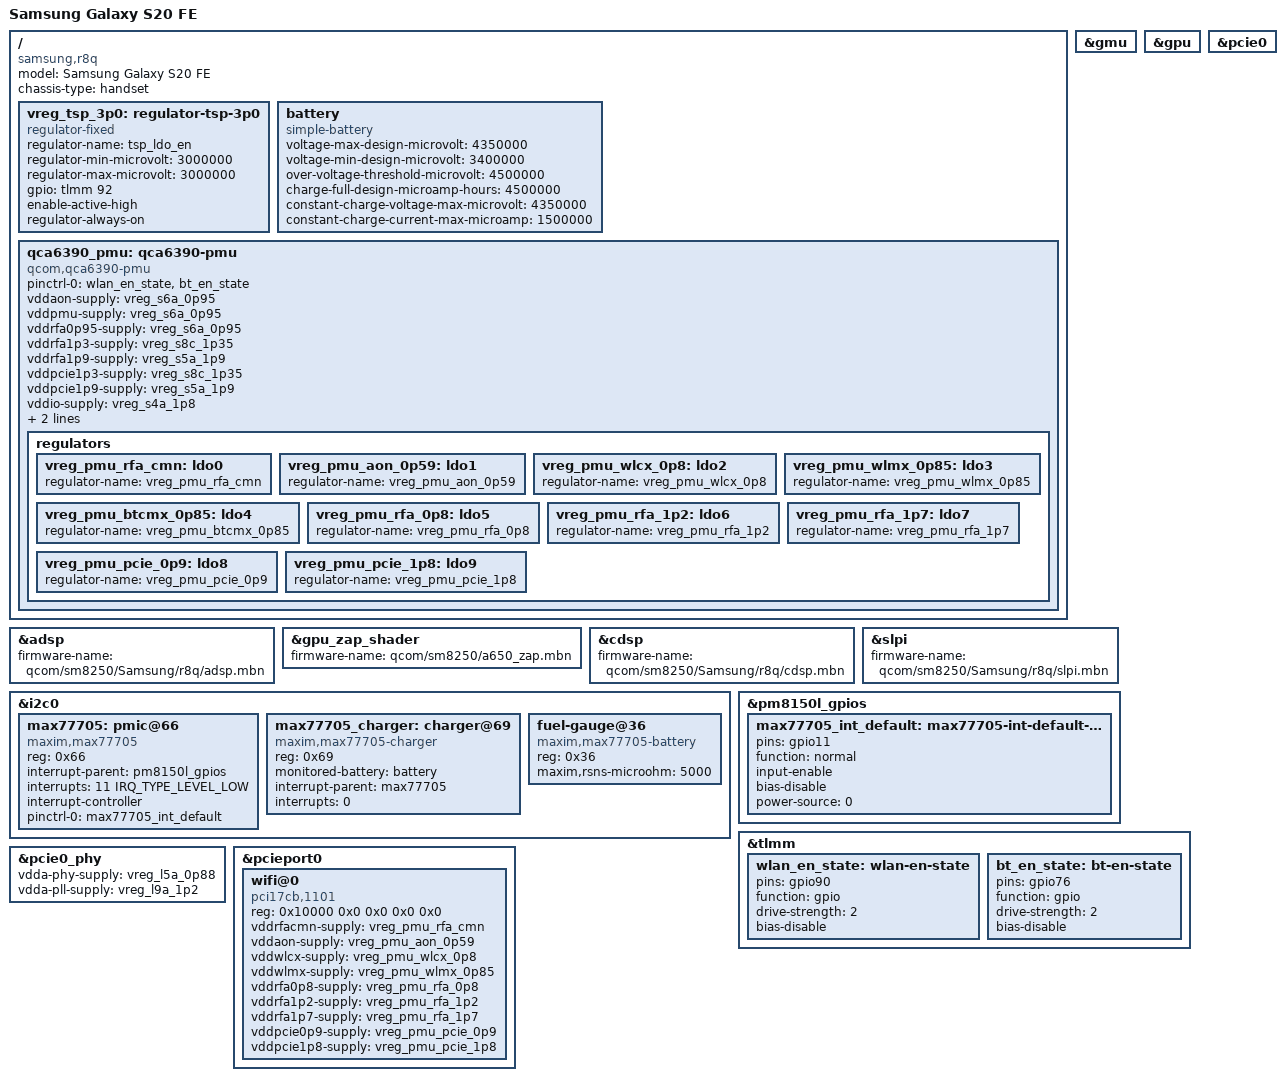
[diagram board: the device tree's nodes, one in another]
// SPDX-License-Identifier: GPL-2.0-only

/dts-v1/;

#include "sm8250-samsung-common.dtsi"

/ {
	model = "Samsung Galaxy S20 FE";
	compatible = "samsung,r8q", "qcom,sm8250";
	chassis-type = "handset";
	/* TSP power: discrete LDO on TLMM 92, always-on for bring-up. */
	vreg_tsp_3p0: regulator-tsp-3p0 {
		compatible = "regulator-fixed";
		regulator-name = "tsp_ldo_en";
		regulator-min-microvolt = <3000000>;
		regulator-max-microvolt = <3000000>;
		gpio = <&tlmm 92 GPIO_ACTIVE_HIGH>;
		enable-active-high;
		regulator-always-on;
	};

	/* EB-BG781ABY pack, 4500 mAh typical. */
	battery: battery {
		compatible = "simple-battery";
		voltage-max-design-microvolt = <4350000>;
		voltage-min-design-microvolt = <3400000>;
		over-voltage-threshold-microvolt = <4500000>;
		charge-full-design-microamp-hours = <4500000>;
		constant-charge-voltage-max-microvolt = <4350000>;
		constant-charge-current-max-microamp = <1500000>;
	};

		qca6390_pmu: qca6390-pmu {
			compatible = "qcom,qca6390-pmu";
	
			pinctrl-names = "default";
			pinctrl-0 = <&wlan_en_state>, <&bt_en_state>;
	
			vddaon-supply = <&vreg_s6a_0p95>;
			vddpmu-supply = <&vreg_s6a_0p95>;
			vddrfa0p95-supply = <&vreg_s6a_0p95>;
			vddrfa1p3-supply = <&vreg_s8c_1p35>;
			vddrfa1p9-supply = <&vreg_s5a_1p9>;
			vddpcie1p3-supply = <&vreg_s8c_1p35>;
			vddpcie1p9-supply = <&vreg_s5a_1p9>;
			vddio-supply = <&vreg_s4a_1p8>;
	
			wlan-enable-gpios = <&tlmm 90 GPIO_ACTIVE_HIGH>;
			bt-enable-gpios = <&tlmm 76 GPIO_ACTIVE_HIGH>;
	
			regulators {
				vreg_pmu_rfa_cmn: ldo0 {
					regulator-name = "vreg_pmu_rfa_cmn";
				};
				vreg_pmu_aon_0p59: ldo1 {
					regulator-name = "vreg_pmu_aon_0p59";
				};
				vreg_pmu_wlcx_0p8: ldo2 {
					regulator-name = "vreg_pmu_wlcx_0p8";
				};
				vreg_pmu_wlmx_0p85: ldo3 {
					regulator-name = "vreg_pmu_wlmx_0p85";
				};
				vreg_pmu_btcmx_0p85: ldo4 {
					regulator-name = "vreg_pmu_btcmx_0p85";
				};
				vreg_pmu_rfa_0p8: ldo5 {
					regulator-name = "vreg_pmu_rfa_0p8";
				};
				vreg_pmu_rfa_1p2: ldo6 {
					regulator-name = "vreg_pmu_rfa_1p2";
				};
				vreg_pmu_rfa_1p7: ldo7 {
					regulator-name = "vreg_pmu_rfa_1p7";
				};
				vreg_pmu_pcie_0p9: ldo8 {
					regulator-name = "vreg_pmu_pcie_0p9";
				};
				vreg_pmu_pcie_1p8: ldo9 {
					regulator-name = "vreg_pmu_pcie_1p8";
				};
			};
		};
};

&adsp {
	firmware-name = "qcom/sm8250/Samsung/r8q/adsp.mbn";
	status = "okay";
};

&gmu {
	status = "okay";
};

&gpu {
	status = "okay";
};

&gpu_zap_shader {
	/* Samsung-signed zap; generic one is rejected by Samsung TZ. */
	firmware-name = "qcom/sm8250/a650_zap.mbn";
};

&cdsp {
	firmware-name = "qcom/sm8250/Samsung/r8q/cdsp.mbn";
	status = "okay";
};

&slpi {
	firmware-name = "qcom/sm8250/Samsung/r8q/slpi.mbn";
	status = "okay";
};

&i2c0 {
	/* SE0 carries the Maxim MAX77705 companion PMIC + fuel gauge. */
	status = "okay";

	max77705: pmic@66 {
		compatible = "maxim,max77705";
		reg = <0x66>;
		interrupt-parent = <&pm8150l_gpios>;
		interrupts = <11 IRQ_TYPE_LEVEL_LOW>;
		interrupt-controller;
		#interrupt-cells = <1>;
		pinctrl-names = "default";
		pinctrl-0 = <&max77705_int_default>;
	};

	max77705_charger: charger@69 {
		compatible = "maxim,max77705-charger";
		reg = <0x69>;
		monitored-battery = <&battery>;
		interrupt-parent = <&max77705>;
		interrupts = <0>;
	};

	/* IRQ-less on purpose: telemetry survives MFD probe failure. */
	fuel-gauge@36 {
		compatible = "maxim,max77705-battery";
		reg = <0x36>;
		maxim,rsns-microohm = <5000>;
	};
};


&pm8150l_gpios {
	max77705_int_default: max77705-int-default-state {
		pins = "gpio11";
		function = "normal";
		input-enable;
		bias-disable;
		power-source = <0>;
	};
};

&tlmm {
	wlan_en_state: wlan-en-state {
		pins = "gpio90";
		function = "gpio";
		drive-strength = <2>;
		bias-disable;
	};

	bt_en_state: bt-en-state {
		pins = "gpio76";
		function = "gpio";
		drive-strength = <2>;
		bias-disable;
	};
};

/* QCA6390 Wi-Fi over PCIe0, driven by ath11k. */
&pcie0 {
	status = "okay";
};

&pcie0_phy {
	vdda-phy-supply = <&vreg_l5a_0p88>;
	vdda-pll-supply = <&vreg_l9a_1p2>;
	status = "okay";
};

&pcieport0 {
	wifi@0 {
		compatible = "pci17cb,1101";
		reg = <0x10000 0x0 0x0 0x0 0x0>;

		vddrfacmn-supply = <&vreg_pmu_rfa_cmn>;
		vddaon-supply = <&vreg_pmu_aon_0p59>;
		vddwlcx-supply = <&vreg_pmu_wlcx_0p8>;
		vddwlmx-supply = <&vreg_pmu_wlmx_0p85>;
		vddrfa0p8-supply = <&vreg_pmu_rfa_0p8>;
		vddrfa1p2-supply = <&vreg_pmu_rfa_1p2>;
		vddrfa1p7-supply = <&vreg_pmu_rfa_1p7>;
		vddpcie0p9-supply = <&vreg_pmu_pcie_0p9>;
		vddpcie1p8-supply = <&vreg_pmu_pcie_1p8>;
	};
};
